AUTOSAR XML (schema 4-2-2)
# Copyright 2016 Mentor Graphics Corporation
# All Rights Reserved
# THIS WORK CONTAINS TRADE SECRET
# AND PROPRIETARY INFORMATION WHICH IS THE
# PROPERTY OF MENTOR GRAPHICS
# CORPORATION OR ITS LICENSORS AND IS
# SUBJECT TO LICENSE TERMS.
package /AUTOSAR/Services/WdgM
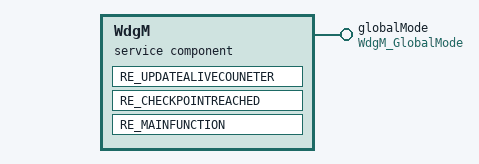
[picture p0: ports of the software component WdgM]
  service sw component type WdgM
    provide port globalMode: provided-interface=WdgM_GlobalMode
    behavior IB_WDGM: data-type-mapping=WdgMModeMappingSet, handle-termination-and-restart=NO-SUPPORT
      runnable RE_UPDATEALIVECOUNETER: can-be-invoked-concurrently=true, symbol=WdgM_UpdateAliveCounter  # Updated entity alive counter
      runnable RE_CHECKPOINTREACHED: can-be-invoked-concurrently=true, symbol=WdgM_CheckpointReached  # invoked whenever there is a checkpoint reported
      runnable RE_MAINFUNCTION: can-be-invoked-concurrently=true, symbol=WdgM_Mainfunction  # Mainfunction
        mode switch point globalMode: mode-group=globalMode.currentMode
  swc implementation IMPL_WdgM: programming-language=C, sw-version=7.2.1, swc-bsw-mapping=SwcBswMapping_WdgM, vendor-id=31, behavior=IB_WDGM
    resource consumption RC_WdgM
      memory section CODE: alignment=UNSPECIFIED, sw-addrmethod=CODE
